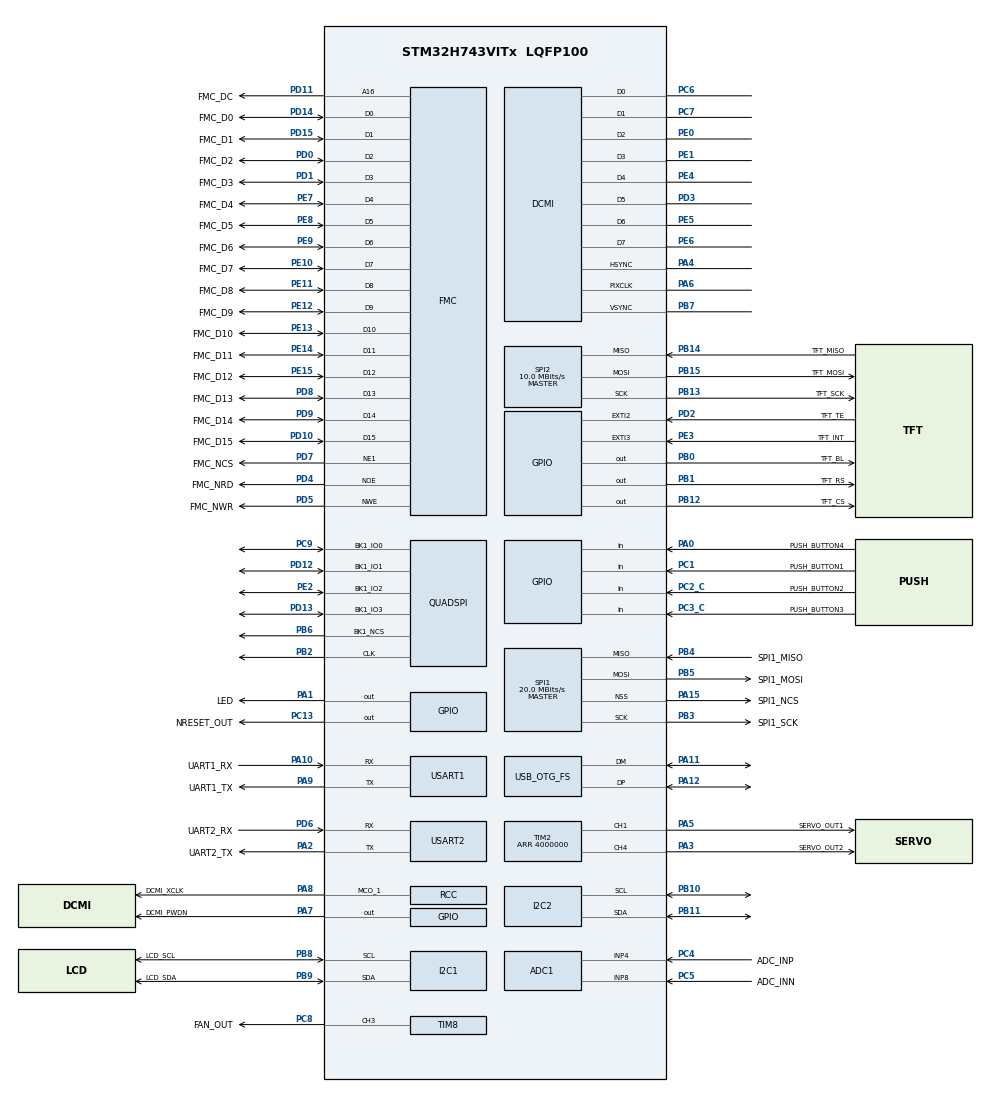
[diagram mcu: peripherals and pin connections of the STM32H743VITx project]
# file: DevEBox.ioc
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ADC1.Channel-0\#ChannelRegularConversion=ADC_CHANNEL_8
ADC1.NbrOfConversionFlag=1
ADC1.OffsetNumber-0\#ChannelRegularConversion=ADC_OFFSET_NONE
ADC1.OffsetSignedSaturation-0\#ChannelRegularConversion=DISABLE
ADC1.Rank-0\#ChannelRegularConversion=1
ADC1.SamplingTime-0\#ChannelRegularConversion=ADC_SAMPLETIME_1CYCLE_5
ADC1.master=1
ADC3.Channel-2\#ChannelRegularConversion=ADC_CHANNEL_TEMPSENSOR
ADC3.ClockPrescalerADC3=ADC_CLOCK_ASYNC_DIV2
ADC3.ContinuousConvMode=ENABLE
ADC3.ConversionDataManagement=ADC_CONVERSIONDATA_DMA_ONESHOT
ADC3.EOCSelection=ADC_EOC_SINGLE_CONV
ADC3.NbrOfConversion=1
ADC3.NbrOfConversionFlag=1
ADC3.OffsetNumber-2\#ChannelRegularConversion=ADC_OFFSET_NONE
ADC3.OffsetSignedSaturation-2\#ChannelRegularConversion=DISABLE
ADC3.Overrun=ADC_OVR_DATA_OVERWRITTEN
ADC3.Rank-2\#ChannelRegularConversion=1
ADC3.SamplingTime-2\#ChannelRegularConversion=ADC_SAMPLETIME_810CYCLES_5
Bdma.ADC3.0.Direction=DMA_PERIPH_TO_MEMORY
Bdma.ADC3.0.EventEnable=DISABLE
Bdma.ADC3.0.Instance=BDMA_Channel0
Bdma.ADC3.0.MemDataAlignment=DMA_MDATAALIGN_HALFWORD
Bdma.ADC3.0.MemInc=DMA_MINC_ENABLE
Bdma.ADC3.0.Mode=DMA_CIRCULAR
Bdma.ADC3.0.PeriphDataAlignment=DMA_PDATAALIGN_HALFWORD
Bdma.ADC3.0.PeriphInc=DMA_PINC_DISABLE
Bdma.ADC3.0.Polarity=HAL_DMAMUX_REQ_GEN_RISING
Bdma.ADC3.0.Priority=DMA_PRIORITY_LOW
Bdma.ADC3.0.RequestNumber=1
Bdma.ADC3.0.SignalID=NONE
Bdma.ADC3.0.SyncEnable=DISABLE
Bdma.ADC3.0.SyncPolarity=HAL_DMAMUX_SYNC_NO_EVENT
Bdma.ADC3.0.SyncRequestNumber=1
Bdma.ADC3.0.SyncSignalID=NONE
Bdma.Request0=ADC3
Bdma.RequestsNb=1
CORTEX_M7.AccessPermission-Cortex_Memory_Protection_Unit_Region0_Settings=MPU_REGION_FULL_ACCESS
CORTEX_M7.AccessPermission-Cortex_Memory_Protection_Unit_Region1_Settings=MPU_REGION_FULL_ACCESS
CORTEX_M7.BaseAddress-Cortex_Memory_Protection_Unit_Region0_Settings=0x38000000
CORTEX_M7.BaseAddress-Cortex_Memory_Protection_Unit_Region1_Settings=0x30000000
CORTEX_M7.CPU_DCache=Enabled
CORTEX_M7.CPU_ICache=Enabled
CORTEX_M7.Enable-Cortex_Memory_Protection_Unit_Region0_Settings=MPU_REGION_ENABLE
CORTEX_M7.Enable-Cortex_Memory_Protection_Unit_Region1_Settings=MPU_REGION_ENABLE
CORTEX_M7.IsShareable-Cortex_Memory_Protection_Unit_Region0_Settings=MPU_ACCESS_SHAREABLE
CORTEX_M7.IsShareable-Cortex_Memory_Protection_Unit_Region1_Settings=MPU_ACCESS_SHAREABLE
CORTEX_M7.MPU_Control=MPU_PRIVILEGED_DEFAULT
CORTEX_M7.Size-Cortex_Memory_Protection_Unit_Region0_Settings=MPU_REGION_SIZE_64KB
CORTEX_M7.Size-Cortex_Memory_Protection_Unit_Region1_Settings=MPU_REGION_SIZE_512KB
CORTEX_M7.TypeExtField-Cortex_Memory_Protection_Unit_Region0_Settings=MPU_TEX_LEVEL1
CORTEX_M7.TypeExtField-Cortex_Memory_Protection_Unit_Region1_Settings=MPU_TEX_LEVEL1
DCMI.PCKPolarity=DCMI_PCKPOLARITY_RISING
DCMI.VSPolarity=DCMI_VSPOLARITY_HIGH
Dma.DCMI.0.Direction=DMA_PERIPH_TO_MEMORY
Dma.DCMI.0.EventEnable=DISABLE
Dma.DCMI.0.FIFOMode=DMA_FIFOMODE_ENABLE
Dma.DCMI.0.FIFOThreshold=DMA_FIFO_THRESHOLD_FULL
Dma.DCMI.0.Instance=DMA2_Stream0
Dma.DCMI.0.MemBurst=DMA_MBURST_SINGLE
Dma.DCMI.0.MemDataAlignment=DMA_MDATAALIGN_WORD
Dma.DCMI.0.MemInc=DMA_MINC_ENABLE
Dma.DCMI.0.Mode=DMA_NORMAL
Dma.DCMI.0.PeriphBurst=DMA_PBURST_SINGLE
Dma.DCMI.0.PeriphDataAlignment=DMA_PDATAALIGN_WORD
Dma.DCMI.0.PeriphInc=DMA_PINC_DISABLE
Dma.DCMI.0.Polarity=HAL_DMAMUX_REQ_GEN_RISING
Dma.DCMI.0.Priority=DMA_PRIORITY_LOW
Dma.DCMI.0.RequestNumber=1
Dma.DCMI.0.SignalID=NONE
Dma.DCMI.0.SyncEnable=DISABLE
Dma.DCMI.0.SyncPolarity=HAL_DMAMUX_SYNC_NO_EVENT
Dma.DCMI.0.SyncRequestNumber=1
Dma.DCMI.0.SyncSignalID=NONE
Dma.Request0=DCMI
Dma.Request1=SPI2_TX
Dma.Request2=USART2_TX
Dma.Request3=USART1_TX
Dma.SPI2_TX.1.Direction=DMA_MEMORY_TO_PERIPH
Dma.SPI2_TX.1.EventEnable=DISABLE
Dma.SPI2_TX.1.FIFOMode=DMA_FIFOMODE_DISABLE
Dma.SPI2_TX.1.Instance=DMA1_Stream0
Dma.SPI2_TX.1.MemDataAlignment=DMA_MDATAALIGN_BYTE
Dma.SPI2_TX.1.MemInc=DMA_MINC_ENABLE
Dma.SPI2_TX.1.Mode=DMA_NORMAL
Dma.SPI2_TX.1.PeriphDataAlignment=DMA_PDATAALIGN_BYTE
Dma.SPI2_TX.1.PeriphInc=DMA_PINC_DISABLE
Dma.SPI2_TX.1.Polarity=HAL_DMAMUX_REQ_GEN_RISING
Dma.SPI2_TX.1.Priority=DMA_PRIORITY_LOW
Dma.SPI2_TX.1.RequestNumber=1
Dma.SPI2_TX.1.SignalID=NONE
Dma.SPI2_TX.1.SyncEnable=DISABLE
Dma.SPI2_TX.1.SyncPolarity=HAL_DMAMUX_SYNC_NO_EVENT
Dma.SPI2_TX.1.SyncRequestNumber=1
Dma.SPI2_TX.1.SyncSignalID=NONE
Dma.USART1_TX.3.Direction=DMA_MEMORY_TO_PERIPH
Dma.USART1_TX.3.EventEnable=DISABLE
Dma.USART1_TX.3.FIFOMode=DMA_FIFOMODE_DISABLE
Dma.USART1_TX.3.Instance=DMA1_Stream2
Dma.USART1_TX.3.MemDataAlignment=DMA_MDATAALIGN_BYTE
Dma.USART1_TX.3.MemInc=DMA_MINC_ENABLE
Dma.USART1_TX.3.Mode=DMA_NORMAL
Dma.USART1_TX.3.PeriphDataAlignment=DMA_PDATAALIGN_BYTE
Dma.USART1_TX.3.PeriphInc=DMA_PINC_DISABLE
Dma.USART1_TX.3.Polarity=HAL_DMAMUX_REQ_GEN_RISING
Dma.USART1_TX.3.Priority=DMA_PRIORITY_LOW
Dma.USART1_TX.3.RequestNumber=1
Dma.USART1_TX.3.SignalID=NONE
Dma.USART1_TX.3.SyncEnable=DISABLE
Dma.USART1_TX.3.SyncPolarity=HAL_DMAMUX_SYNC_NO_EVENT
Dma.USART1_TX.3.SyncRequestNumber=1
Dma.USART1_TX.3.SyncSignalID=NONE
Dma.USART2_TX.2.Direction=DMA_MEMORY_TO_PERIPH
Dma.USART2_TX.2.EventEnable=DISABLE
Dma.USART2_TX.2.FIFOMode=DMA_FIFOMODE_DISABLE
Dma.USART2_TX.2.Instance=DMA1_Stream1
Dma.USART2_TX.2.MemDataAlignment=DMA_MDATAALIGN_BYTE
Dma.USART2_TX.2.MemInc=DMA_MINC_ENABLE
Dma.USART2_TX.2.Mode=DMA_NORMAL
Dma.USART2_TX.2.PeriphDataAlignment=DMA_PDATAALIGN_BYTE
Dma.USART2_TX.2.PeriphInc=DMA_PINC_DISABLE
Dma.USART2_TX.2.Polarity=HAL_DMAMUX_REQ_GEN_RISING
Dma.USART2_TX.2.Priority=DMA_PRIORITY_LOW
Dma.USART2_TX.2.RequestNumber=1
Dma.USART2_TX.2.SignalID=NONE
Dma.USART2_TX.2.SyncEnable=DISABLE
Dma.USART2_TX.2.SyncPolarity=HAL_DMAMUX_SYNC_NO_EVENT
Dma.USART2_TX.2.SyncRequestNumber=1
Dma.USART2_TX.2.SyncSignalID=NONE
I2C1.Timing=0x10C0ECFF
I2C2.Timing=0x10C0ECFF
Mcu.Family=STM32H7
Mcu.Name=STM32H743VITx
Mcu.Package=LQFP100
NVIC.BDMA_Channel0_IRQn=true\:0\:0\:false\:false\:true\:false\:true\:true
NVIC.DCMI_IRQn=true\:0\:0\:false\:false\:true\:true\:true\:true
NVIC.DMA1_Stream0_IRQn=true\:0\:0\:false\:false\:true\:false\:true\:true
NVIC.DMA1_Stream1_IRQn=true\:0\:0\:false\:false\:true\:false\:true\:true
NVIC.DMA1_Stream2_IRQn=true\:0\:0\:false\:false\:true\:false\:true\:true
NVIC.DMA2D_IRQn=true\:0\:0\:false\:false\:true\:true\:true\:true
NVIC.DMA2_Stream0_IRQn=true\:0\:0\:false\:false\:true\:false\:true\:true
NVIC.OTG_FS_IRQn=true\:0\:0\:false\:false\:true\:false\:true\:true
NVIC.PriorityGroup=NVIC_PRIORITYGROUP_4
NVIC.SPI2_IRQn=true\:0\:0\:false\:false\:true\:true\:true\:true
NVIC.TIM1_UP_IRQn=true\:15\:0\:false\:false\:true\:false\:true\:true
NVIC.TimeBase=TIM1_UP_IRQn
NVIC.TimeBaseIP=TIM1
NVIC.USART1_IRQn=true\:0\:0\:false\:false\:true\:true\:true\:true
NVIC.USART2_IRQn=true\:0\:0\:false\:false\:true\:true\:true\:true
PA0.GPIO_Label=PUSH_BUTTON4
PA0.GPIO_PuPd=GPIO_PULLUP
PA0.Signal=GPIO_Input
PA1.GPIO_Label=LED
PA1.GPIO_ModeDefaultOutputPP=GPIO_MODE_OUTPUT_PP
PA1.PinState=GPIO_PIN_SET
PA1.Signal=GPIO_Output
PA10.GPIO_Label=UART1_RX
PA10.GPIO_PuPd=GPIO_PULLUP
PA10.Mode=Asynchronous
PA10.Signal=USART1_RX
PA11.Mode=Device_Only
PA11.Signal=USB_OTG_FS_DM
PA12.Mode=Device_Only
PA12.Signal=USB_OTG_FS_DP
PA13\ (JTMS/SWDIO).Mode=Serial_Wire
PA13\ (JTMS/SWDIO).Signal=DEBUG_JTMS-SWDIO
PA14\ (JTCK/SWCLK).Mode=Serial_Wire
PA14\ (JTCK/SWCLK).Signal=DEBUG_JTCK-SWCLK
PA15\ (JTDI).GPIO_Label=SPI1_NCS
PA15\ (JTDI).Mode=NSS_Signal_Hard_Output
PA15\ (JTDI).Signal=SPI1_NSS
PA2.GPIO_Label=UART2_TX
PA2.Mode=Asynchronous
PA2.Signal=USART2_TX
PA3.GPIO_Label=SERVO_OUT2
PA3.Signal=S_TIM2_CH4
PA4.Mode=Slave_8_bits_External_Synchro
PA4.Signal=DCMI_HSYNC
PA5.GPIO_Label=SERVO_OUT1
PA5.Signal=S_TIM2_CH1_ETR
PA6.Mode=Slave_8_bits_External_Synchro
PA6.Signal=DCMI_PIXCLK
PA7.GPIO_Label=DCMI_PWDN
PA7.Signal=GPIO_Output
PA8.GPIO_Label=DCMI_XCLK
PA8.GPIO_Speed=GPIO_SPEED_FREQ_VERY_HIGH
PA8.Mode=Clock-out-1
PA8.Signal=RCC_MCO_1
PA9.GPIO_Label=UART1_TX
PA9.Mode=Asynchronous
PA9.Signal=USART1_TX
PB0.GPIO_Label=TFT_BL
PB0.Signal=GPIO_Output
PB1.GPIO_Label=TFT_RS
PB1.Signal=GPIO_Output
PB10.GPIO_Pu=GPIO_PULLUP
PB10.GPIO_Speed=GPIO_SPEED_FREQ_HIGH
PB10.Mode=I2C
PB10.Signal=I2C2_SCL
PB11.GPIO_Pu=GPIO_PULLUP
PB11.GPIO_Speed=GPIO_SPEED_FREQ_HIGH
PB11.Mode=I2C
PB11.Signal=I2C2_SDA
PB12.GPIO_Label=TFT_CS
PB12.Signal=GPIO_Output
PB13.GPIO_Label=TFT_SCK
PB13.Mode=Full_Duplex_Master
PB13.Signal=SPI2_SCK
PB14.GPIO_Label=TFT_MISO
PB14.Mode=Full_Duplex_Master
PB14.Signal=SPI2_MISO
PB15.GPIO_Label=TFT_MOSI
PB15.Mode=Full_Duplex_Master
PB15.Signal=SPI2_MOSI
PB2.GPIO_Speed=GPIO_SPEED_FREQ_VERY_HIGH
PB2.Mode=Single Bank 1
PB2.Signal=QUADSPI_CLK
PB3\ (JTDO/TRACESWO).GPIO_Label=SPI1_SCK
PB3\ (JTDO/TRACESWO).Mode=Full_Duplex_Master
PB3\ (JTDO/TRACESWO).Signal=SPI1_SCK
PB4\ (NJTRST).GPIO_Label=SPI1_MISO
PB4\ (NJTRST).Mode=Full_Duplex_Master
PB4\ (NJTRST).Signal=SPI1_MISO
PB5.GPIO_Label=SPI1_MOSI
PB5.Mode=Full_Duplex_Master
PB5.Signal=SPI1_MOSI
PB6.GPIO_PuPd=GPIO_PULLUP
PB6.GPIO_Speed=GPIO_SPEED_FREQ_VERY_HIGH
PB6.Mode=Single Bank 1
PB6.Signal=QUADSPI_BK1_NCS
PB7.Mode=Slave_8_bits_External_Synchro
PB7.Signal=DCMI_VSYNC
PB8.GPIO_Label=LCD_SCL
PB8.GPIO_Pu=GPIO_PULLUP
PB8.GPIO_Speed=GPIO_SPEED_FREQ_HIGH
PB8.Mode=I2C
PB8.Signal=I2C1_SCL
PB9.GPIO_Label=LCD_SDA
PB9.GPIO_Pu=GPIO_PULLUP
PB9.GPIO_Speed=GPIO_SPEED_FREQ_HIGH
PB9.Mode=I2C
PB9.Signal=I2C1_SDA
PC1.GPIO_Label=PUSH_BUTTON1
PC1.GPIO_PuPd=GPIO_PULLUP
PC1.Signal=GPIO_Input
PC13.GPIO_Label=NRESET_OUT
PC13.Signal=GPIO_Output
PC2_C.GPIO_Label=PUSH_BUTTON2
PC2_C.GPIO_PuPd=GPIO_PULLUP
PC2_C.Signal=GPIO_Input
PC3_C.GPIO_Label=PUSH_BUTTON3
PC3_C.GPIO_PuPd=GPIO_PULLUP
PC3_C.Signal=GPIO_Input
PC4.GPIO_Label=ADC_INP
PC4.Signal=ADCx_INP4
PC5.GPIO_Label=ADC_INN
PC5.Signal=ADCx_INP8
PC6.Mode=Slave_8_bits_External_Synchro
PC6.Signal=DCMI_D0
PC7.Mode=Slave_8_bits_External_Synchro
PC7.Signal=DCMI_D1
PC8.GPIO_Label=FAN_OUT
PC8.Signal=S_TIM8_CH3
PC9.GPIO_Speed=GPIO_SPEED_FREQ_VERY_HIGH
PC9.Mode=Single Bank 1
PC9.Signal=QUADSPI_BK1_IO0
PD0.GPIO_Label=FMC_D2
PD0.Signal=FMC_D2_DA2
PD1.GPIO_Label=FMC_D3
PD1.Signal=FMC_D3_DA3
PD10.GPIO_Label=FMC_D15
PD10.Signal=FMC_D15_DA15
PD11.GPIO_Label=FMC_DC
PD11.Signal=FMC_A16_CLE
PD12.GPIO_Speed=GPIO_SPEED_FREQ_VERY_HIGH
PD12.Mode=Single Bank 1
PD12.Signal=QUADSPI_BK1_IO1
PD13.GPIO_Speed=GPIO_SPEED_FREQ_VERY_HIGH
PD13.Mode=Single Bank 1
PD13.Signal=QUADSPI_BK1_IO3
PD14.GPIO_Label=FMC_D0
PD14.Signal=FMC_D0_DA0
PD15.GPIO_Label=FMC_D1
PD15.Signal=FMC_D1_DA1
PD2.GPIO_Label=TFT_TE
PD2.GPIO_PuPd=GPIO_PULLUP
PD2.Signal=GPXTI2
PD3.Mode=Slave_8_bits_External_Synchro
PD3.Signal=DCMI_D5
PD4.GPIO_Label=FMC_NRD
PD4.Signal=FMC_NOE
PD5.GPIO_Label=FMC_NWR
PD5.Signal=FMC_NWE
PD6.GPIO_Label=UART2_RX
PD6.GPIO_PuPd=GPIO_PULLUP
PD6.Mode=Asynchronous
PD6.Signal=USART2_RX
PD7.GPIO_Label=FMC_NCS
PD7.Mode=NorPsramChipSelect1_1
PD7.Signal=FMC_NE1
PD8.GPIO_Label=FMC_D13
PD8.Signal=FMC_D13_DA13
PD9.GPIO_Label=FMC_D14
PD9.Signal=FMC_D14_DA14
PE0.Mode=Slave_8_bits_External_Synchro
PE0.Signal=DCMI_D2
PE1.Mode=Slave_8_bits_External_Synchro
PE1.Signal=DCMI_D3
PE10.GPIO_Label=FMC_D7
PE10.Signal=FMC_D7_DA7
PE11.GPIO_Label=FMC_D8
PE11.Signal=FMC_D8_DA8
PE12.GPIO_Label=FMC_D9
PE12.Signal=FMC_D9_DA9
PE13.GPIO_Label=FMC_D10
PE13.Signal=FMC_D10_DA10
PE14.GPIO_Label=FMC_D11
PE14.Signal=FMC_D11_DA11
PE15.GPIO_Label=FMC_D12
PE15.Signal=FMC_D12_DA12
PE2.GPIO_Speed=GPIO_SPEED_FREQ_VERY_HIGH
PE2.Mode=Single Bank 1
PE2.Signal=QUADSPI_BK1_IO2
PE3.GPIO_Label=TFT_INT
PE3.Signal=GPXTI3
PE4.Mode=Slave_8_bits_External_Synchro
PE4.Signal=DCMI_D4
PE5.Mode=Slave_8_bits_External_Synchro
PE5.Signal=DCMI_D6
PE6.Mode=Slave_8_bits_External_Synchro
PE6.Signal=DCMI_D7
PE7.GPIO_Label=FMC_D4
PE7.Signal=FMC_D4_DA4
PE8.GPIO_Label=FMC_D5
PE8.Signal=FMC_D5_DA5
PE9.GPIO_Label=FMC_D6
PE9.Signal=FMC_D6_DA6
PH0-OSC_IN\ (PH0).Mode=HSE-External-Oscillator
PH0-OSC_IN\ (PH0).Signal=RCC_OSC_IN
PH1-OSC_OUT\ (PH1).Mode=HSE-External-Oscillator
PH1-OSC_OUT\ (PH1).Signal=RCC_OSC_OUT
ProjectManager.HeapSize=0x800
ProjectManager.StackSize=0x800
ProjectManager.TargetToolchain=STM32CubeIDE
QUADSPI.ClockPrescaler=2
QUADSPI.FifoThreshold=4
QUADSPI.FlashSize=22
RCC.ADCFreq_Value=96000000
RCC.APB1Freq_Value=100000000
RCC.APB2Freq_Value=100000000
RCC.APB3Freq_Value=100000000
RCC.APB4Freq_Value=100000000
RCC.CortexFreq_Value=400000000
RCC.D1PPRE=RCC_APB3_DIV2
RCC.D2PPRE1=RCC_APB1_DIV2
RCC.D2PPRE2=RCC_APB2_DIV2
RCC.D3PPRE=RCC_APB4_DIV2
RCC.DIVM1=5
RCC.DIVM2=25
RCC.DIVM3=25
RCC.DIVN1=160
RCC.DIVN2=192
RCC.DIVN3=192
RCC.DIVQ1=20
RCC.DIVQ3=4
RCC.HCLKFreq_Value=200000000
RCC.HPRE=RCC_HCLK_DIV2
RCC.HSE_VALUE=25000000
RCC.PLL2FRACN=0
RCC.PLL3FRACN=0
RCC.PLLFRACN=0
RCC.PLLSourceVirtual=RCC_PLLSOURCE_HSE
RCC.RCC_MCO1Source=RCC_MCO1SOURCE_HSE
RCC.RCC_MCODiv1=RCC_MCODIV_5
RCC.SYSCLKFreq_VALUE=400000000
RCC.SYSCLKSource=RCC_SYSCLKSOURCE_PLLCLK
RCC.USBCLockSelection=RCC_USBCLKSOURCE_PLL3
RCC.USBFreq_Value=48000000
SH.ADCx_INP4.0=ADC1_INP4,IN4-Single-Ended
SH.ADCx_INP8.0=ADC1_INP8,IN8-Single-Ended
SH.FMC_A16_CLE.0=FMC_A16,A16_1
SH.FMC_D0_DA0.0=FMC_D0,16b-d1
SH.FMC_D10_DA10.0=FMC_D10,16b-d1
SH.FMC_D11_DA11.0=FMC_D11,16b-d1
SH.FMC_D12_DA12.0=FMC_D12,16b-d1
SH.FMC_D13_DA13.0=FMC_D13,16b-d1
SH.FMC_D14_DA14.0=FMC_D14,16b-d1
SH.FMC_D15_DA15.0=FMC_D15,16b-d1
SH.FMC_D1_DA1.0=FMC_D1,16b-d1
SH.FMC_D2_DA2.0=FMC_D2,16b-d1
SH.FMC_D3_DA3.0=FMC_D3,16b-d1
SH.FMC_D4_DA4.0=FMC_D4,16b-d1
SH.FMC_D5_DA5.0=FMC_D5,16b-d1
SH.FMC_D6_DA6.0=FMC_D6,16b-d1
SH.FMC_D7_DA7.0=FMC_D7,16b-d1
SH.FMC_D8_DA8.0=FMC_D8,16b-d1
SH.FMC_D9_DA9.0=FMC_D9,16b-d1
SH.FMC_NOE.0=FMC_NOE,Lcd1
SH.FMC_NWE.0=FMC_NWE,Lcd1
SH.S_TIM2_CH1_ETR.0=TIM2_CH1,PWM Generation1 CH1
SH.S_TIM2_CH4.0=TIM2_CH4,PWM Generation4 CH4
SH.S_TIM8_CH3.0=TIM8_CH3,PWM Generation3 CH3
SPI1.CalculateBaudRate=20.0 MBits/s
SPI1.Direction=SPI_DIRECTION_2LINES
SPI1.Mode=SPI_MODE_MASTER
SPI1.VirtualNSS=VM_NSSHARD
SPI1.VirtualType=VM_MASTER
SPI2.BaudRatePrescaler=SPI_BAUDRATEPRESCALER_4
SPI2.CalculateBaudRate=10.0 MBits/s
SPI2.DataSize=SPI_DATASIZE_8BIT
SPI2.Direction=SPI_DIRECTION_2LINES
SPI2.MasterKeepIOState=SPI_MASTER_KEEP_IO_STATE_ENABLE
SPI2.Mode=SPI_MODE_MASTER
SPI2.VirtualType=VM_MASTER
STMicroelectronics.X-CUBE-AI.10.0.0.ActivationBufferSizeList=231432
STMicroelectronics.X-CUBE-AI.10.0.0.ActivationBuffers=pool0
STMicroelectronics.X-CUBE-AI.10.0.0.ActivationNames=pool0
STMicroelectronics.X-CUBE-AI.10.0.0.ActivationSizes=AI_NETWORK_DATA_ACTIVATION_1_SIZE
STMicroelectronics.X-CUBE-AI.10.0.0.HeapSize=0x800
STMicroelectronics.X-CUBE-AI.10.0.0.InternalRamActivationBufferMaxSize=AI_NETWORK_DATA_ACTIVATIONS_SIZE
STMicroelectronics.X-CUBE-AI.10.0.0.LatestDirectoryUsed-a9730470acbd773448e9ec48d2d065f000c2769d15c24c9269137879c38b4974=C\:\\OneDrive\\Desktop\\Jeil\\ARM-STM32\\STM32AI\\stm32ai-modelzoo\\object_detection\\st_yolo_x\\ST_pretrainedmodel_public_dataset\\coco_2017_person\\st_yolo_x_nano_192
STMicroelectronics.X-CUBE-AI.10.0.0.MaximumNumberOfInputLayer=1
STMicroelectronics.X-CUBE-AI.10.0.0.MaximumNumberOfOutputLayer=1
STMicroelectronics.X-CUBE-AI.10.0.0.MaximumSizeOfInputLayer=1
STMicroelectronics.X-CUBE-AI.10.0.0.MaximumSizeOfOutputLayer=1,1,1
STMicroelectronics.X-CUBE-AI.10.0.0.ModelActualCompression-a9730470acbd773448e9ec48d2d065f000c2769d15c24c9269137879c38b4974=0.0
STMicroelectronics.X-CUBE-AI.10.0.0.ModelCompression-a9730470acbd773448e9ec48d2d065f000c2769d15c24c9269137879c38b4974=None
STMicroelectronics.X-CUBE-AI.10.0.0.ModelFlashOccupation-a9730470acbd773448e9ec48d2d065f000c2769d15c24c9269137879c38b4974=1082929
STMicroelectronics.X-CUBE-AI.10.0.0.ModelHashList=a9730470acbd773448e9ec48d2d065f000c2769d15c24c9269137879c38b4974
STMicroelectronics.X-CUBE-AI.10.0.0.ModelKind-a9730470acbd773448e9ec48d2d065f000c2769d15c24c9269137879c38b4974=TFLITE
STMicroelectronics.X-CUBE-AI.10.0.0.ModelMacc-a9730470acbd773448e9ec48d2d065f000c2769d15c24c9269137879c38b4974=112230814
STMicroelectronics.X-CUBE-AI.10.0.0.ModelName-a9730470acbd773448e9ec48d2d065f000c2769d15c24c9269137879c38b4974=network_1745982922300
STMicroelectronics.X-CUBE-AI.10.0.0.ModelNameList=network_1745982922300
STMicroelectronics.X-CUBE-AI.10.0.0.ModelRamOccupation-a9730470acbd773448e9ec48d2d065f000c2769d15c24c9269137879c38b4974=231432
STMicroelectronics.X-CUBE-AI.10.0.0.ModelStructureFile-a9730470acbd773448e9ec48d2d065f000c2769d15c24c9269137879c38b4974=C\:\\OneDrive\\Desktop\\Jeil\\ARM-STM32\\STM32AI\\stm32ai-modelzoo\\object_detection\\st_yolo_x\\ST_pretrainedmodel_public_dataset\\coco_2017_person\\st_yolo_x_nano_192\\st_yolo_x_nano_192_0.33_0.25_int8.tflite
STMicroelectronics.X-CUBE-AI.10.0.0.ModelType-a9730470acbd773448e9ec48d2d065f000c2769d15c24c9269137879c38b4974=STM32Cube.AI MCU runtime
STMicroelectronics.X-CUBE-AI.10.0.0.ReadyForCodeGeneration=true
STMicroelectronics.X-CUBE-AI.10.0.0.StackSize=0x800
STMicroelectronics.X-CUBE-AI.10.0.0.WorkingBufferStartAddrList=0xFFFFFFFF
STMicroelectronics.X-CUBE-AI.10.0.0.copyWeightToRam=false
STMicroelectronics.X-CUBE-AI.10.0.0.copyWeightToRam-a9730470acbd773448e9ec48d2d065f000c2769d15c24c9269137879c38b4974=false
STMicroelectronics.X-CUBE-AI.10.0.0.customLayerConfigEnabled=false
STMicroelectronics.X-CUBE-AI.10.0.0.customLayerConfigEnabled-a9730470acbd773448e9ec48d2d065f000c2769d15c24c9269137879c38b4974=false
STMicroelectronics.X-CUBE-AI.10.0.0.noOnnxIoTranspose=false
STMicroelectronics.X-CUBE-AI.10.0.0.noOnnxIoTranspose-a9730470acbd773448e9ec48d2d065f000c2769d15c24c9269137879c38b4974=false
STMicroelectronics.X-CUBE-AI.10.0.0.useInputAllocation=true
STMicroelectronics.X-CUBE-AI.10.0.0.useInputAllocation-a9730470acbd773448e9ec48d2d065f000c2769d15c24c9269137879c38b4974=true
STMicroelectronics.X-CUBE-AI.10.0.0.useOutputAllocation=true
STMicroelectronics.X-CUBE-AI.10.0.0.useOutputAllocation-a9730470acbd773448e9ec48d2d065f000c2769d15c24c9269137879c38b4974=true
TIM2.Channel-PWM\ Generation1\ CH1=TIM_CHANNEL_1
TIM2.Channel-PWM\ Generation4\ CH4=TIM_CHANNEL_4
TIM2.OCPolarity_1=TIM_OCPOLARITY_LOW
TIM2.OCPolarity_4=TIM_OCPOLARITY_LOW
TIM2.Period=4000000
TIM2.Pulse-PWM\ Generation1\ CH1=300000
TIM2.Pulse-PWM\ Generation4\ CH4=300000
TIM8.Break2Polarity=TIM_BREAK2POLARITY_LOW
TIM8.Channel-PWM\ Generation3\ CH3=TIM_CHANNEL_3
TIM8.Period=10000
TIM8.Pulse-PWM\ Generation3\ CH3=5000
USART1.VirtualMode-Asynchronous=VM_ASYNC
USART2.VirtualMode-Asynchronous=VM_ASYNC
USB_DEVICE.CLASS_NAME_FS=CDC
USB_DEVICE.VirtualMode-CDC_FS=Cdc
USB_DEVICE.VirtualModeFS=Cdc_FS
USB_OTG_FS.VirtualMode=Device_Only
USB_OTG_FS.dma_enable=DISABLE
VP_ADC3_TempSens_Input.Mode=IN-TempSens
VP_ADC3_Vref_Input.Mode=IN-Vrefint
VP_DMA2D_VS_DMA2D.Mode=DMA2D_Activate
VP_MEMORYMAP_VS_MEMORYMAP.Mode=CurAppReg
VP_SYS_VS_tim1.Mode=TIM1
VP_TIM2_VS_ClockSourceINT.Mode=Internal
VP_TIM8_VS_ClockSourceINT.Mode=Internal
VP_USB_DEVICE_VS_USB_DEVICE_CDC_FS.Mode=CDC_FS
board=custom

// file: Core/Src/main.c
/* USER CODE BEGIN Header */
/**
 ******************************************************************************
 * @file           : main.c
 * @brief          : Main program body
 ******************************************************************************
 * @attention
 *
 * Copyright (c) 2025 STMicroelectronics.
 * All rights reserved.
 *
 * This software is licensed under terms that can be found in the LICENSE file
 * in the root directory of this software component.
 * If no LICENSE file comes with this software, it is provided AS-IS.
 *
 ******************************************************************************
 */
/* USER CODE END Header */
#include "main.h"
#include "adc.h"
#include "bdma.h"
#include "dcmi.h"
#include "dma.h"
#include "dma2d.h"
#include "i2c.h"
#include "memorymap.h"
#include "quadspi.h"
#include "spi.h"
#include "tim.h"
#include "usart.h"
#include "usb_device.h"
#include "gpio.h"
#include "fmc.h"

/* USER CODE BEGIN Includes */
#include "i2c-lcd.h"
#include "debug_console.h"
#include "ov7670.h"
#include "AS7265X.h"

/* USER CODE END Includes */

/* USER CODE BEGIN PTD */
#define	_USE_TFT_	1
#define	_USE_LCD_	1

/* USER CODE END PTD */

/* USER CODE BEGIN PV */
extern uint32_t frame_counter;
extern uint8_t img_buffer[];
char LCD_Busy = 0;
uint32_t new_frame_counter = 0;

void LCD_IO_DmaTxCpltCallback(SPI_HandleTypeDef *hspi)
{
	LCD_Busy = 0;
}

void RefreshCamera()
{
	if ((!LCD_Busy)&&(new_frame_counter!=frame_counter))
	{
		if ((frame_counter-new_frame_counter)>1)
		{
			DebugPrint("\r\n %8lX %8lX", frame_counter, new_frame_counter);
		}
		LCD_Busy = 0;
		new_frame_counter = frame_counter;
		BSP_LCD_DrawRGB16Image(0, 0, 320, 240, (uint16_t *)img_buffer);
	}
}

/* USER CODE END PV */

void SystemClock_Config(void);
void PeriphCommonClock_Config(void);
static void MPU_Config(void);

/* USER CODE BEGIN 0 */
void SetServoPos(uint8_t servo_no, int16_t pos)
{
	if (pos>1000)
		pos = 1000;
	if (pos<-1000)
		pos = -1000;

	uint32_t duty = 300000l + (200l * pos);
	switch (servo_no) {
	case 1:
		((TIM_HandleTypeDef*)&SERVO_TIMER_HANDLE)->Instance->CCR1 = duty;
		break;
	case 2:
		((TIM_HandleTypeDef*)&SERVO_TIMER_HANDLE)->Instance->CCR4 = duty;
		break;
	}
}

void SetFanDuty(float duty)
{
	if (duty>100.0f)
		duty = 100.0f;

	uint32_t _duty = duty * (10000/100.0f);
	((TIM_HandleTypeDef*)&FAN_TIMER_HANDLE)->Instance->CCR3 = _duty;
}

/* USER CODE END 0 */

int main(void)
{

  /* MPU Configuration--------------------------------------------------------*/
  MPU_Config();

  /* Enable the CPU Cache */

  /* Enable I-Cache---------------------------------------------------------*/
  SCB_EnableICache();

  /* Enable D-Cache---------------------------------------------------------*/
  SCB_EnableDCache();

  /* MCU Configuration--------------------------------------------------------*/

  /* Reset of all peripherals, Initializes the Flash interface and the Systick. */
  HAL_Init();

  /* Configure the system clock */
  SystemClock_Config();

  /* Configure the peripherals common clocks */
  PeriphCommonClock_Config();

  /* Initialize all configured peripherals */
  MX_GPIO_Init();
  MX_BDMA_Init();
  MX_DMA_Init();
  MX_QUADSPI_Init();
  MX_ADC3_Init();
  MX_USB_DEVICE_Init();
  MX_USART1_UART_Init();
  MX_I2C2_Init();
  MX_DCMI_Init();
  MX_SPI2_Init();
  MX_DMA2D_Init();
  MX_I2C1_Init();
  MX_FMC_Init();
  MX_USART2_UART_Init();
  MX_SPI1_Init();
  MX_TIM2_Init();
  MX_ADC1_Init();
  MX_TIM8_Init();
  /* USER CODE BEGIN 2 */
#if	_USE_TFT_
	BSP_LCD_Init();
	BSP_LCD_DisplayOn();
	{
		uint32_t size = 320l * 240 * 2;
		memset(img_buffer, 0, size);
	}
#endif
#if	_USE_LCD_
	lcd_init();
#endif
  /* USER CODE END 2 */

  /* Infinite loop */
  /* USER CODE BEGIN WHILE */
	AS7265X_begin(&hi2c_as7265x);

	HAL_GPIO_WritePin(CAMERA_PWDN_GPIO_Port, CAMERA_PWDN_Pin, GPIO_PIN_RESET);
	HAL_GPIO_WritePin(CAMERA_RESET_GPIO_Port, CAMERA_RESET_Pin, GPIO_PIN_SET);

	DebugInit();
	{
		OV7670_Init(&hdcmi, &hi2c_dcmi, 0, 0);
		OV7670_Start();
	}

	{
		HAL_TIM_Base_Start(&SERVO_TIMER_HANDLE);
		HAL_TIM_PWM_Start(&SERVO_TIMER_HANDLE, TIM_CHANNEL_1);
		HAL_TIM_PWM_Start(&SERVO_TIMER_HANDLE, TIM_CHANNEL_4);
		HAL_TIM_Base_Start(&FAN_TIMER_HANDLE);
		HAL_TIM_PWM_Start(&FAN_TIMER_HANDLE, TIM_CHANNEL_3);
		SetServoPos(1,0);
		SetServoPos(2,0);
	}

	int counter = 0;
	int position = 1000;

	while (1)
	{
		counter++;
		if (counter>10)
		{
			counter = 0;
			position = -position;
			SetServoPos(1,position);
			SetServoPos(2,position);
			DebugPrint("\r\n SetServoPos(1,%d);", position);
		}

    /* USER CODE END WHILE */

    /* USER CODE BEGIN 3 */
		//HAL_GPIO_WritePin(LED_GPIO_Port, LED_Pin, GPIO_PIN_SET);
		HAL_Delay(100);
		DebugTask();
		RefreshCamera();
		//HAL_GPIO_WritePin(LED_GPIO_Port, LED_Pin, GPIO_PIN_RESET);
		HAL_Delay(100);
		DebugTask();
		RefreshCamera();
		uint32_t ADC_val = CalcTemperature();
		if (ADC_val > 0)
		{
			char buffer[40];
			sprintf(buffer, "\r\n ADC_val = %10ld", ADC_val);
			HAL_UART_Transmit(&huart_ADC, (uint8_t*) buffer, strlen(buffer), 100);
#if	_USE_TFT_
//			uint8_t *header = (uint8_t*) "      ADC_Val     ";
//			BSP_LCD_DisplayStringAtLine(2, header);
//			sprintf(buffer, "   %10ld   ", ADC_val);
//			BSP_LCD_DisplayStringAtLine(4, (uint8_t*) buffer);
#endif
#if	_USE_LCD_
			lcd_put_cur(0, 0);
			lcd_send_string("    ADC_Val     ");
			lcd_put_cur(1, 0);
			sprintf(buffer, "   %8ld   ", ADC_val);
			lcd_send_string(buffer);
#endif
		}
	}
  /* USER CODE END 3 */
}

void SystemClock_Config(void)
{
  RCC_OscInitTypeDef RCC_OscInitStruct = {0};
  RCC_ClkInitTypeDef RCC_ClkInitStruct = {0};

  /** Supply configuration update enable
  */
  HAL_PWREx_ConfigSupply(PWR_LDO_SUPPLY);

  /** Configure the main internal regulator output voltage
  */
  __HAL_PWR_VOLTAGESCALING_CONFIG(PWR_REGULATOR_VOLTAGE_SCALE1);

  while(!__HAL_PWR_GET_FLAG(PWR_FLAG_VOSRDY)) {}

  /** Initializes the RCC Oscillators according to the specified parameters
  * in the RCC_OscInitTypeDef structure.
  */
  RCC_OscInitStruct.OscillatorType = RCC_OSCILLATORTYPE_HSE;
  RCC_OscInitStruct.HSEState = RCC_HSE_ON;
  RCC_OscInitStruct.PLL.PLLState = RCC_PLL_ON;
  RCC_OscInitStruct.PLL.PLLSource = RCC_PLLSOURCE_HSE;
  RCC_OscInitStruct.PLL.PLLM = 5;
  RCC_OscInitStruct.PLL.PLLN = 160;
  RCC_OscInitStruct.PLL.PLLP = 2;
  RCC_OscInitStruct.PLL.PLLQ = 20;
  RCC_OscInitStruct.PLL.PLLR = 2;
  RCC_OscInitStruct.PLL.PLLRGE = RCC_PLL1VCIRANGE_2;
  RCC_OscInitStruct.PLL.PLLVCOSEL = RCC_PLL1VCOWIDE;
  RCC_OscInitStruct.PLL.PLLFRACN = 0;
  if (HAL_RCC_OscConfig(&RCC_OscInitStruct) != HAL_OK)
  {
    Error_Handler();
  }

  /** Initializes the CPU, AHB and APB buses clocks
  */
  RCC_ClkInitStruct.ClockType = RCC_CLOCKTYPE_HCLK|RCC_CLOCKTYPE_SYSCLK
                              |RCC_CLOCKTYPE_PCLK1|RCC_CLOCKTYPE_PCLK2
                              |RCC_CLOCKTYPE_D3PCLK1|RCC_CLOCKTYPE_D1PCLK1;
  RCC_ClkInitStruct.SYSCLKSource = RCC_SYSCLKSOURCE_PLLCLK;
  RCC_ClkInitStruct.SYSCLKDivider = RCC_SYSCLK_DIV1;
  RCC_ClkInitStruct.AHBCLKDivider = RCC_HCLK_DIV2;
  RCC_ClkInitStruct.APB3CLKDivider = RCC_APB3_DIV2;
  RCC_ClkInitStruct.APB1CLKDivider = RCC_APB1_DIV2;
  RCC_ClkInitStruct.APB2CLKDivider = RCC_APB2_DIV2;
  RCC_ClkInitStruct.APB4CLKDivider = RCC_APB4_DIV2;

  if (HAL_RCC_ClockConfig(&RCC_ClkInitStruct, FLASH_LATENCY_2) != HAL_OK)
  {
    Error_Handler();
  }
  HAL_RCC_MCOConfig(RCC_MCO1, RCC_MCO1SOURCE_HSE, RCC_MCODIV_5);
}

void PeriphCommonClock_Config(void)
{
  RCC_PeriphCLKInitTypeDef PeriphClkInitStruct = {0};

  /** Initializes the peripherals clock
  */
  PeriphClkInitStruct.PeriphClockSelection = RCC_PERIPHCLK_ADC;
  PeriphClkInitStruct.PLL2.PLL2M = 25;
  PeriphClkInitStruct.PLL2.PLL2N = 192;
  PeriphClkInitStruct.PLL2.PLL2P = 2;
  PeriphClkInitStruct.PLL2.PLL2Q = 2;
  PeriphClkInitStruct.PLL2.PLL2R = 2;
  PeriphClkInitStruct.PLL2.PLL2RGE = RCC_PLL2VCIRANGE_0;
  PeriphClkInitStruct.PLL2.PLL2VCOSEL = RCC_PLL2VCOWIDE;
  PeriphClkInitStruct.PLL2.PLL2FRACN = 0;
  PeriphClkInitStruct.AdcClockSelection = RCC_ADCCLKSOURCE_PLL2;
  if (HAL_RCCEx_PeriphCLKConfig(&PeriphClkInitStruct) != HAL_OK)
  {
    Error_Handler();
  }
}

/* USER CODE BEGIN 4 */
void DebugMain(uint32_t val)
{
	switch (val)
	{
	case 0:
	{
		DebugPrint("\r\n OV7670_Start()");
		//OV7670_Init(&hdcmi, &hi2c_dcmi, 0, 0);
		OV7670_Start();
	}
		break;
	case 1:
	{
		uint8_t temp1, temp2;
		if (ov7670_read(OV7670_REG_PID, &temp1) == HAL_OK)
		{
			ov7670_read(OV7670_REG_VER, &temp2);
			DebugPrint("\r\n ReadID %02X %02X", temp1, temp2);
		}
		else
		{
			DebugPrint("\r\n ReadID Error!");
		}
	}
		break;
	case 2:
	{
		if (OV7670_isDriverBusy())
		{
			DebugPrint("\r\n OV7670_isDriver is Busy");
		}
		else
		{
			DebugPrint("\r\n OV7670_isDriver is NOY Busy");
		}
	}
		break;
	case 3:
	{
		DebugPrint("\r\n Start Servos");
		HAL_TIM_Base_Start(&htim2);
		HAL_TIM_PWM_Start(&htim2, TIM_CHANNEL_1);
		HAL_TIM_PWM_Start(&htim2, TIM_CHANNEL_4);
	}
		break;
	case 4:
	{
		DebugPrint("\r\n Clearing img_buffer");
		uint32_t size = 320l * 240 * 2;
		memset(img_buffer, 0, size);
	}
		break;
	case 5:
	{
		DebugPrint("\r\n BSP_LCD_DrawRGB16Image");
		BSP_LCD_DrawRGB16Image(0, 0, 320, 240, (uint16_t *)img_buffer);
	}
		break;
	case 6:
	case 9:
	{
		uint8_t servo_no = (val - 3)/3;
		DebugPrint("\r\n SetServoPos(%d,1000);", servo_no);
		SetServoPos(servo_no,1000);
	}
		break;
	case 7:
	case 10:
	{
		uint8_t servo_no = (val - 4)/3;
		DebugPrint("\r\n SetServoPos(%d,0);", servo_no);
		SetServoPos(servo_no,0);
	}
		break;
	case 8:
	case 11:
	{
		uint8_t servo_no = (val - 5)/3;
		DebugPrint("\r\n SetServoPos(%d,-1000);", servo_no);
		SetServoPos(servo_no,-1000);
	}
		break;
	}
}
/* USER CODE END 4 */

 /* MPU Configuration */

void MPU_Config(void)
{
  MPU_Region_InitTypeDef MPU_InitStruct = {0};

  /* Disables the MPU */
  HAL_MPU_Disable();

  /** Initializes and configures the Region and the memory to be protected
  */
  MPU_InitStruct.Enable = MPU_REGION_ENABLE;
  MPU_InitStruct.Number = MPU_REGION_NUMBER0;
  MPU_InitStruct.BaseAddress = 0x38000000;
  MPU_InitStruct.Size = MPU_REGION_SIZE_64KB;
  MPU_InitStruct.SubRegionDisable = 0x0;
  MPU_InitStruct.TypeExtField = MPU_TEX_LEVEL1;
  MPU_InitStruct.AccessPermission = MPU_REGION_FULL_ACCESS;
  MPU_InitStruct.DisableExec = MPU_INSTRUCTION_ACCESS_ENABLE;
  MPU_InitStruct.IsShareable = MPU_ACCESS_SHAREABLE;
  MPU_InitStruct.IsCacheable = MPU_ACCESS_NOT_CACHEABLE;
  MPU_InitStruct.IsBufferable = MPU_ACCESS_NOT_BUFFERABLE;

  HAL_MPU_ConfigRegion(&MPU_InitStruct);

  /** Initializes and configures the Region and the memory to be protected
  */
  MPU_InitStruct.Number = MPU_REGION_NUMBER1;
  MPU_InitStruct.BaseAddress = 0x30000000;
  MPU_InitStruct.Size = MPU_REGION_SIZE_512KB;

  HAL_MPU_ConfigRegion(&MPU_InitStruct);
  /* Enables the MPU */
  HAL_MPU_Enable(MPU_PRIVILEGED_DEFAULT);

}

void HAL_TIM_PeriodElapsedCallback(TIM_HandleTypeDef *htim)
{
  if (htim->Instance == TIM1)
  {
    HAL_IncTick();
  }
}

void Error_Handler(void)
{
	__disable_irq();
	while (1)
	{
	}
}
